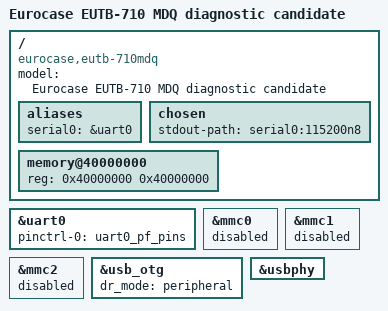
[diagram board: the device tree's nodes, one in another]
// SPDX-License-Identifier: (GPL-2.0+ OR MIT)
// Diagnostic candidate: compiled only; no board-level hardware validation.
/dts-v1/;
#include "sun8i-a23.dtsi"

/ {
    model = "Eurocase EUTB-710 MDQ diagnostic candidate";
    compatible = "eurocase,eutb-710mdq", "allwinner,sun8i-a23";
    aliases { serial0 = &uart0; };
    chosen { stdout-path = "serial0:115200n8"; };
    memory@40000000 {
        device_type = "memory";
        reg = <0x40000000 0x40000000>;
    };
};

// Stock FEX debug UART uses PF2/PF4, which overlap MMC0.
&uart0 {
    pinctrl-names = "default";
    pinctrl-0 = <&uart0_pf_pins>;
    status = "okay";
};

&mmc0 { status = "disabled"; };
&mmc1 { status = "disabled"; };
&mmc2 { status = "disabled"; };

// USB gadget support requires a matching kernel/initramfs and VBUS validation.
&usb_otg {
    dr_mode = "peripheral";
    status = "okay";
};
&usbphy { status = "okay"; };
